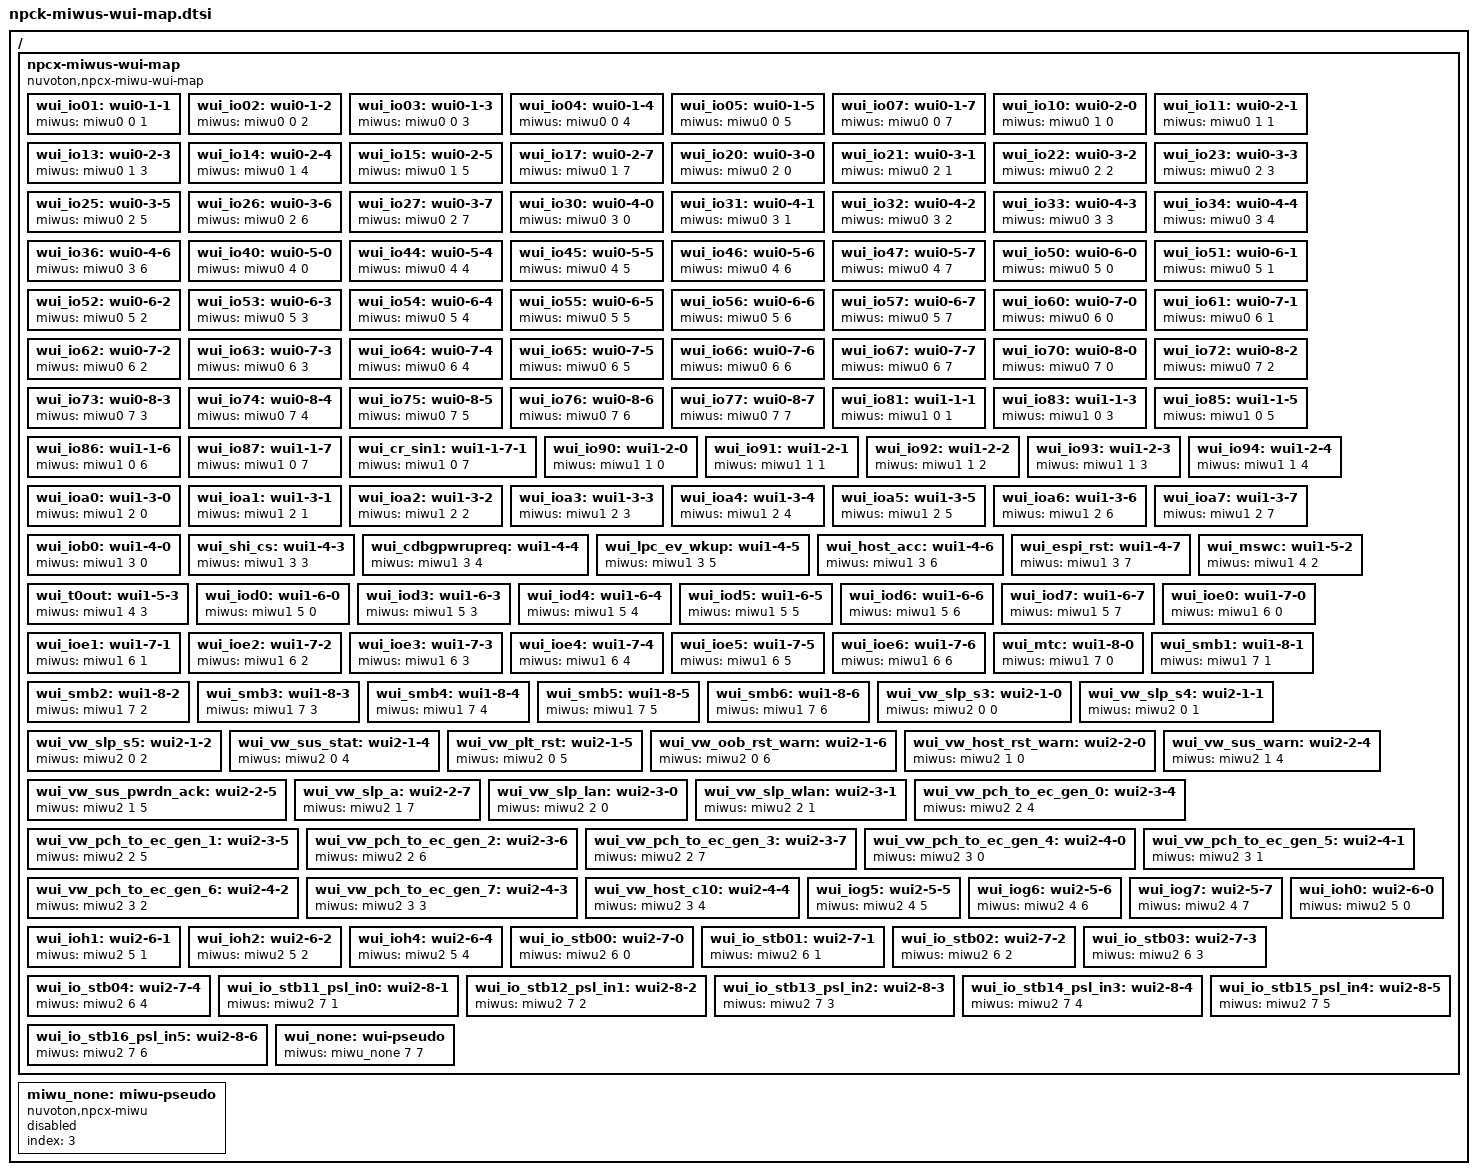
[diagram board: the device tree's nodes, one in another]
/*
 * Copyright (c) 2025 Nuvoton Technology Corporation.
 *
 * SPDX-License-Identifier: Apache-2.0
 */

/ {
	/* Mapping between MIWU wui bits and source device */
	npcx-miwus-wui-map {
		compatible = "nuvoton,npcx-miwu-wui-map";

		/* MIWU table 0 */
		/* MIWU group A */
		wui_io01: wui0-1-1 {
			miwus = <&miwu0 0 1>; /* GPIO01 */
		};

		wui_io02: wui0-1-2 {
			miwus = <&miwu0 0 2>; /* GPIO02 */
		};

		wui_io03: wui0-1-3 {
			miwus = <&miwu0 0 3>; /* GPIO03 */
		};

		wui_io04: wui0-1-4 {
			miwus = <&miwu0 0 4>; /* GPIO04 */
		};

		wui_io05: wui0-1-5 {
			miwus = <&miwu0 0 5>; /* GPIO05 */
		};

		wui_io07: wui0-1-7 {
			miwus = <&miwu0 0 7>; /* GPIO07 */
		};

		/* MIWU group B */
		wui_io10: wui0-2-0 {
			miwus = <&miwu0 1 0>; /* GPIO10 */
		};

		wui_io11: wui0-2-1 {
			miwus = <&miwu0 1 1>; /* GPIO11 */
		};

		wui_io13: wui0-2-3 {
			miwus = <&miwu0 1 3>; /* GPIO13 */
		};

		wui_io14: wui0-2-4 {
			miwus = <&miwu0 1 4>; /* GPIO14 */
		};

		wui_io15: wui0-2-5 {
			miwus = <&miwu0 1 5>; /* GPIO15 */
		};

		wui_io17: wui0-2-7 {
			miwus = <&miwu0 1 7>; /* GPIO17 */
		};

		/* MIWU group C */
		wui_io20: wui0-3-0 {
			miwus = <&miwu0 2 0>; /* GPIO20 */
		};

		wui_io21: wui0-3-1 {
			miwus = <&miwu0 2 1>; /* GPIO21 */
		};

		wui_io22: wui0-3-2 {
			miwus = <&miwu0 2 2>; /* GPIO22 */
		};

		wui_io23: wui0-3-3 {
			miwus = <&miwu0 2 3>; /* GPIO23 */
		};

		wui_io25: wui0-3-5 {
			miwus = <&miwu0 2 5>; /* GPIO25 */
		};

		wui_io26: wui0-3-6 {
			miwus = <&miwu0 2 6>; /* GPIO26 */
		};

		wui_io27: wui0-3-7 {
			miwus = <&miwu0 2 7>; /* GPIO27 */
		};

		/* MIWU group D */
		wui_io30: wui0-4-0 {
			miwus = <&miwu0 3 0>; /* GPIO30 */
		};

		wui_io31: wui0-4-1 {
			miwus = <&miwu0 3 1>; /* GPIO31 */
		};

		wui_io32: wui0-4-2 {
			miwus = <&miwu0 3 2>; /* GPIO32 */
		};

		wui_io33: wui0-4-3 {
			miwus = <&miwu0 3 3>; /* GPIO33 */
		};

		wui_io34: wui0-4-4 {
			miwus = <&miwu0 3 4>; /* GPIO34 */
		};

		wui_io36: wui0-4-6 {
			miwus = <&miwu0 3 6>; /* GPIO36 */
		};

		/* MIWU group E */
		wui_io40: wui0-5-0 {
			miwus = <&miwu0 4 0>; /* GPIO40 */
		};

		wui_io44: wui0-5-4 {
			miwus = <&miwu0 4 4>; /* GPIO44 */
		};

		wui_io45: wui0-5-5 {
			miwus = <&miwu0 4 5>; /* GPIO45 */
		};

		wui_io46: wui0-5-6 {
			miwus = <&miwu0 4 6>; /* GPIO46 */
		};

		wui_io47: wui0-5-7 {
			miwus = <&miwu0 4 7>; /* GPIO47 */
		};

		/* MIWU group F */
		wui_io50: wui0-6-0 {
			miwus = <&miwu0 5 0>; /* GPIO50 */
		};

		wui_io51: wui0-6-1 {
			miwus = <&miwu0 5 1>; /* GPIO51 */
		};

		wui_io52: wui0-6-2 {
			miwus = <&miwu0 5 2>; /* GPIO52 */
		};

		wui_io53: wui0-6-3 {
			miwus = <&miwu0 5 3>; /* GPIO53 */
		};

		wui_io54: wui0-6-4 {
			miwus = <&miwu0 5 4>; /* GPIO54 */
		};

		wui_io55: wui0-6-5 {
			miwus = <&miwu0 5 5>; /* GPIO55 */
		};

		wui_io56: wui0-6-6 {
			miwus = <&miwu0 5 6>; /* GPIO56 */
		};

		wui_io57: wui0-6-7 {
			miwus = <&miwu0 5 7>; /* GPIO57 */
		};

		/* MIWU group G */
		wui_io60: wui0-7-0 {
			miwus = <&miwu0 6 0>; /* GPIO60 */
		};

		wui_io61: wui0-7-1 {
			miwus = <&miwu0 6 1>; /* GPIO61 */
		};

		wui_io62: wui0-7-2 {
			miwus = <&miwu0 6 2>; /* GPIO62 */
		};

		wui_io63: wui0-7-3 {
			miwus = <&miwu0 6 3>; /* GPIO63 */
		};

		wui_io64: wui0-7-4 {
			miwus = <&miwu0 6 4>; /* GPIO64 */
		};

		wui_io65: wui0-7-5 {
			miwus = <&miwu0 6 5>; /* GPIO65 */
		};

		wui_io66: wui0-7-6 {
			miwus = <&miwu0 6 6>; /* GPIO66 */
		};

		wui_io67: wui0-7-7 {
			miwus = <&miwu0 6 7>; /* GPIO67 */
		};

		/* MIWU group H */
		wui_io70: wui0-8-0 {
			miwus = <&miwu0 7 0>; /* GPIO70 */
		};

		wui_io72: wui0-8-2 {
			miwus = <&miwu0 7 2>; /* GPIO72 */
		};

		wui_io73: wui0-8-3 {
			miwus = <&miwu0 7 3>; /* GPIO73 */
		};

		wui_io74: wui0-8-4 {
			miwus = <&miwu0 7 4>; /* GPIO74 */
		};

		wui_io75: wui0-8-5 {
			miwus = <&miwu0 7 5>; /* GPIO75 */
		};

		wui_io76: wui0-8-6 {
			miwus = <&miwu0 7 6>; /* GPIO76 */
		};

		wui_io77: wui0-8-7 {
			miwus = <&miwu0 7 7>; /* GPIO77 */
		};

		/* MIWU table 1 */
		/* MIWU group A */
		wui_io81: wui1-1-1 {
			miwus = <&miwu1 0 1>; /* GPIO81 */
		};

		wui_io83: wui1-1-3 {
			miwus = <&miwu1 0 3>; /* GPIO83 */
		};

		wui_io85: wui1-1-5 {
			miwus = <&miwu1 0 5>; /* GPIO85 */
		};

		wui_io86: wui1-1-6 {
			miwus = <&miwu1 0 6>; /* GPIO86 */
		};

		wui_io87: wui1-1-7 {
			miwus = <&miwu1 0 7>; /* GPIO87 */
		};

		wui_cr_sin1: wui1-1-7-1 {
			miwus = <&miwu1 0 7>; /* CR_SIN */
		};

		/* MIWU group B */
		wui_io90: wui1-2-0 {
			miwus = <&miwu1 1 0>; /* GPIO90 */
		};

		wui_io91: wui1-2-1 {
			miwus = <&miwu1 1 1>; /* GPIO91 */
		};

		wui_io92: wui1-2-2 {
			miwus = <&miwu1 1 2>; /* GPIO92 */
		};

		wui_io93: wui1-2-3 {
			miwus = <&miwu1 1 3>; /* GPIO93 */
		};

		wui_io94: wui1-2-4 {
			miwus = <&miwu1 1 4>; /* GPIO94 */
		};

		/* MIWU group C */
		wui_ioa0: wui1-3-0 {
			miwus = <&miwu1 2 0>; /* GPIOA0 */
		};

		wui_ioa1: wui1-3-1 {
			miwus = <&miwu1 2 1>; /* GPIOA1 */
		};

		wui_ioa2: wui1-3-2 {
			miwus = <&miwu1 2 2>; /* GPIOA2 */
		};

		wui_ioa3: wui1-3-3 {
			miwus = <&miwu1 2 3>; /* GPIOA3 */
		};

		wui_ioa4: wui1-3-4 {
			miwus = <&miwu1 2 4>; /* GPIOA4 */
		};

		wui_ioa5: wui1-3-5 {
			miwus = <&miwu1 2 5>; /* GPIOA5 */
		};

		wui_ioa6: wui1-3-6 {
			miwus = <&miwu1 2 6>; /* GPIOA6 */
		};

		wui_ioa7: wui1-3-7 {
			miwus = <&miwu1 2 7>; /* GPIOA7 */
		};

		/* MIWU group D */
		wui_iob0: wui1-4-0 {
			miwus = <&miwu1 3 0>; /* GPIOB0 */
		};

		wui_shi_cs: wui1-4-3 {
			miwus = <&miwu1 3 3>; /* SHI_CS */
		};

		wui_cdbgpwrupreq: wui1-4-4 {
			miwus = <&miwu1 3 4>; /* CDBGPWRUPREQ */
		};

		wui_lpc_ev_wkup: wui1-4-5 {
			miwus = <&miwu1 3 5>; /* LPC_EV_WKUP */
		};

		wui_host_acc: wui1-4-6 {
			miwus = <&miwu1 3 6>; /* HOST_ACC */
		};

		wui_espi_rst: wui1-4-7 {
			miwus = <&miwu1 3 7>; /* ESPI_RST */
		};

		/* MIWU group E */
		wui_mswc: wui1-5-2 {
			miwus = <&miwu1 4 2>; /* MSWC */
		};

		wui_t0out: wui1-5-3 {
			miwus = <&miwu1 4 3>; /* T0OUT */
		};

		/* MIWU group F */
		wui_iod0: wui1-6-0 {
			miwus = <&miwu1 5 0>; /* GPIOD0 */
		};

		wui_iod3: wui1-6-3 {
			miwus = <&miwu1 5 3>; /* GPIOD3 */
		};

		wui_iod4: wui1-6-4 {
			miwus = <&miwu1 5 4>; /* GPIOD4 */
		};

		wui_iod5: wui1-6-5 {
			miwus = <&miwu1 5 5>; /* GPIOD5 */
		};

		wui_iod6: wui1-6-6 {
			miwus = <&miwu1 5 6>; /* GPIOD6 */
		};

		wui_iod7: wui1-6-7 {
			miwus = <&miwu1 5 7>; /* GPIOD7 */
		};

		/* MIWU group G */
		wui_ioe0: wui1-7-0 {
			miwus = <&miwu1 6 0>; /* GPIOE0 */
		};

		wui_ioe1: wui1-7-1 {
			miwus = <&miwu1 6 1>; /* GPIOE1 */
		};

		wui_ioe2: wui1-7-2 {
			miwus = <&miwu1 6 2>; /* GPIOE2 */
		};

		wui_ioe3: wui1-7-3 {
			miwus = <&miwu1 6 3>; /* GPIOE3 */
		};

		wui_ioe4: wui1-7-4 {
			miwus = <&miwu1 6 4>; /* GPIOE4 */
		};

		wui_ioe5: wui1-7-5 {
			miwus = <&miwu1 6 5>; /* GPIOE5 */
		};

		wui_ioe6: wui1-7-6 {
			miwus = <&miwu1 6 6>; /* GPIOE6 */
		};

		/* MIWU group H */
		wui_mtc: wui1-8-0 {
			miwus = <&miwu1 7 0>; /* MTC */
		};

		wui_smb1: wui1-8-1 {
			miwus = <&miwu1 7 1>; /* SMB1 */
		};

		wui_smb2: wui1-8-2 {
			miwus = <&miwu1 7 2>; /* SMB2 */
		};

		wui_smb3: wui1-8-3 {
			miwus = <&miwu1 7 3>; /* SMB3 */
		};

		wui_smb4: wui1-8-4 {
			miwus = <&miwu1 7 4>; /* SMB4 */
		};

		wui_smb5: wui1-8-5 {
			miwus = <&miwu1 7 5>; /* SMB5 */
		};

		wui_smb6: wui1-8-6 {
			miwus = <&miwu1 7 6>; /* SMB6 */
		};

		/* MIWU table 2 */
		/* MIWU group A */
		wui_vw_slp_s3: wui2-1-0 {
			miwus = <&miwu2 0 0>; /* SLP_S3_L */
		};

		wui_vw_slp_s4: wui2-1-1 {
			miwus = <&miwu2 0 1>; /* SLP_S4_L */
		};

		wui_vw_slp_s5: wui2-1-2 {
			miwus = <&miwu2 0 2>; /* SLP_S5_L */
		};

		wui_vw_sus_stat: wui2-1-4 {
			miwus = <&miwu2 0 4>; /* SUS_STAT_L */
		};

		wui_vw_plt_rst: wui2-1-5 {
			miwus = <&miwu2 0 5>; /* PLTRST_L */
		};

		wui_vw_oob_rst_warn: wui2-1-6 {
			miwus = <&miwu2 0 6>; /* OOB_RST_WARN */
		};

		/* MIWU group B */
		wui_vw_host_rst_warn: wui2-2-0 {
			miwus = <&miwu2 1 0>; /* HOST_RST_WARN */
		};

		wui_vw_sus_warn: wui2-2-4 {
			miwus = <&miwu2 1 4>; /* SUS_WARN_L */
		};

		wui_vw_sus_pwrdn_ack: wui2-2-5 {
			miwus = <&miwu2 1 5>; /* SUS_PWRDN_ACK */
		};

		wui_vw_slp_a: wui2-2-7 {
			miwus = <&miwu2 1 7>; /* SLP_A_L */
		};

		/* MIWU group C */
		wui_vw_slp_lan: wui2-3-0 {
			miwus = <&miwu2 2 0>; /* SLP_LAN_L */
		};

		wui_vw_slp_wlan: wui2-3-1 {
			miwus = <&miwu2 2 1>; /* SLP_WLAN_L */
		};

		wui_vw_pch_to_ec_gen_0: wui2-3-4 {
			miwus = <&miwu2 2 4>; /* PCH_TO_EC_GENERIC_0 */
		};

		wui_vw_pch_to_ec_gen_1: wui2-3-5 {
			miwus = <&miwu2 2 5>; /* PCH_TO_EC_GENERIC_1 */
		};

		wui_vw_pch_to_ec_gen_2: wui2-3-6 {
			miwus = <&miwu2 2 6>; /* PCH_TO_EC_GENERIC_2 */
		};

		wui_vw_pch_to_ec_gen_3: wui2-3-7 {
			miwus = <&miwu2 2 7>; /* PCH_TO_EC_GENERIC_3 */
		};

		/* MIWU group D */
		wui_vw_pch_to_ec_gen_4: wui2-4-0 {
			miwus = <&miwu2 3 0>; /* PCH_TO_EC_GENERIC_4 */
		};

		wui_vw_pch_to_ec_gen_5: wui2-4-1 {
			miwus = <&miwu2 3 1>; /* PCH_TO_EC_GENERIC_5 */
		};

		wui_vw_pch_to_ec_gen_6: wui2-4-2 {
			miwus = <&miwu2 3 2>; /* PCH_TO_EC_GENERIC_6 */
		};

		wui_vw_pch_to_ec_gen_7: wui2-4-3 {
			miwus = <&miwu2 3 3>; /* PCH_TO_EC_GENERIC_7 */
		};

		wui_vw_host_c10: wui2-4-4 {
			miwus = <&miwu2 3 4>; /* HOST_C10 */
		};

		/* MIWU group E */
		wui_iog5: wui2-5-5 {
			miwus = <&miwu2 4 5>; /* GPIOG5 */
		};

		wui_iog6: wui2-5-6 {
			miwus = <&miwu2 4 6>; /* GPIOG6 */
		};

		wui_iog7: wui2-5-7 {
			miwus = <&miwu2 4 7>; /* GPIOG7 */
		};

		/* MIWU group F */
		wui_ioh0: wui2-6-0 {
			miwus = <&miwu2 5 0>; /* GPIOH0 */
		};

		wui_ioh1: wui2-6-1 {
			miwus = <&miwu2 5 1>; /* GPIOH1 */
		};

		wui_ioh2: wui2-6-2 {
			miwus = <&miwu2 5 2>; /* GPIOH2 */
		};

		wui_ioh4: wui2-6-4 {
			miwus = <&miwu2 5 4>; /* GPIOH4 */
		};

		/* MIWU group G */
		wui_io_stb00: wui2-7-0 {
			miwus = <&miwu2 6 0>; /* GPIO_STB00 */
		};

		wui_io_stb01: wui2-7-1 {
			miwus = <&miwu2 6 1>; /* GPIO_STB01 */
		};

		wui_io_stb02: wui2-7-2 {
			miwus = <&miwu2 6 2>; /* GPIO_STB02 */
		};

		wui_io_stb03: wui2-7-3 {
			miwus = <&miwu2 6 3>; /* GPIO_STB03 */
		};

		wui_io_stb04: wui2-7-4 {
			miwus = <&miwu2 6 4>; /* GPIO_STB04 */
		};

		/* MIWU group H */
		wui_io_stb11_psl_in0: wui2-8-1 {
			miwus = <&miwu2 7 1>; /* GPIO_STB11/PSL_IN0 */
		};

		wui_io_stb12_psl_in1: wui2-8-2 {
			miwus = <&miwu2 7 2>; /* GPIO_STB12/PSL_IN1 */
		};

		wui_io_stb13_psl_in2: wui2-8-3 {
			miwus = <&miwu2 7 3>; /* GPIO_STB13/PSL_IN2 */
		};

		wui_io_stb14_psl_in3: wui2-8-4 {
			miwus = <&miwu2 7 4>; /* GPIO_STB14/PSL_IN3 */
		};

		wui_io_stb15_psl_in4: wui2-8-5 {
			miwus = <&miwu2 7 5>; /* GPIO_STB15/PSL_IN4 */
		};

		wui_io_stb16_psl_in5: wui2-8-6 {
			miwus = <&miwu2 7 6>; /* GPIO_STB16/PSL_IN5 */
		};

		/* Pseudo wui item means no mapping between source and wui */
		wui_none: wui-pseudo {
			miwus = <&miwu_none 7 7>;
		};
	};

	/* Pseudo MIWU device to present no mapping relationship */
	miwu_none: miwu-pseudo {
		compatible = "nuvoton,npcx-miwu";
		index = <3>;
		#miwu-cells = <2>;
		status = "disabled";
	};
};
